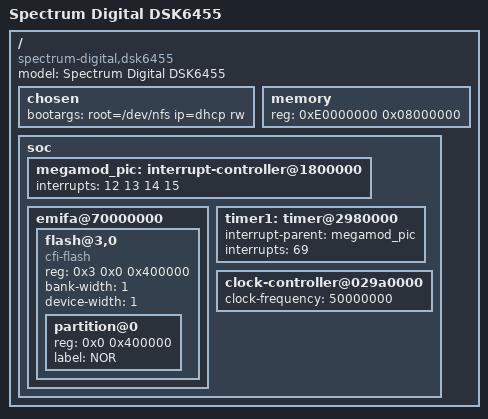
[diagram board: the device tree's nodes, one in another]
// SPDX-License-Identifier: GPL-2.0-or-later
/*
 * arch/c6x/boot/dts/dsk6455.dts
 *
 * DSK6455 Evaluation Platform For TMS320C6455
 * Copyright (C) 2011 Texas Instruments Incorporated
 *
 * Author: Mark Salter <msalter@redhat.com>
 */

/dts-v1/;

/include/ "tms320c6455.dtsi"

/ {
	model = "Spectrum Digital DSK6455";
	compatible = "spectrum-digital,dsk6455";

	chosen {
		bootargs = "root=/dev/nfs ip=dhcp rw";
	};

	memory {
		device_type = "memory";
		reg = <0xE0000000 0x08000000>;
	};

	soc {
		megamod_pic: interrupt-controller@1800000 {
			interrupts = < 12 13 14 15 >;
		};

		emifa@70000000 {
			flash@3,0 {
				  #address-cells = <1>;
				#size-cells = <1>;
				compatible = "cfi-flash";
				reg = <0x3 0x0 0x400000>;
				bank-width = <1>;
				device-width = <1>;
				partition@0 {
					reg = <0x0 0x400000>;
					label = "NOR";
				};
			};
		};

		timer1: timer@2980000 {
			interrupt-parent = <&megamod_pic>;
			interrupts = < 69 >;
		};

		clock-controller@029a0000 {
			clock-frequency = <50000000>;
		};
	};
};
